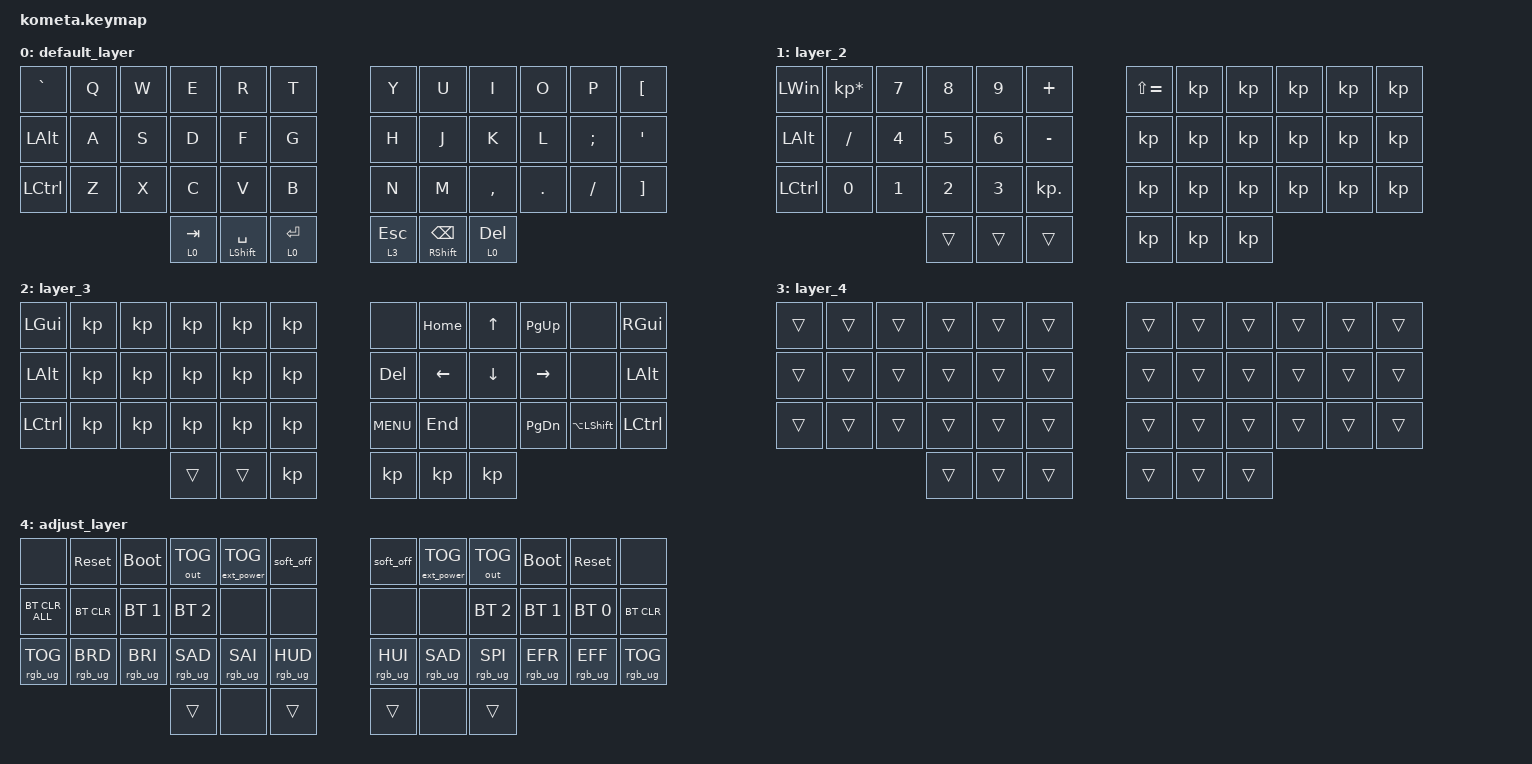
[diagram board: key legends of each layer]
#include <behaviors.dtsi>
#include <dt-bindings/zmk/bt.h>
#include <dt-bindings/zmk/ext_power.h>
#include <dt-bindings/zmk/keys.h>
#include <dt-bindings/zmk/outputs.h>
#include <dt-bindings/zmk/rgb.h>

#define DEF 0
#define LWR 1
#define RSE 2
#define ADJ 3

/ {
};

/ {
    behaviors {
        hr: hr {
            compatible = "zmk,behavior-hold-tap";
            label = "home_row";
            bindings = <&kp>, <&kp>;

            #binding-cells = <2>;
            tapping-term-ms = <150>;
            quick-tap-ms = <250>;
            flavor = "tap-preferred";
        };

        copy: copy {
            compatible = "zmk,behavior-tap-dance";
            label = "COPY";
            #binding-cells = <0>;
            bindings = <&kp C>, <&kp K_COPY>;
        };

        paste: paste {
            compatible = "zmk,behavior-tap-dance";
            label = "PASTE";
            #binding-cells = <0>;
            bindings = <&kp V>, <&kp INSERT>;
        };
    };

    keymap {
        compatible = "zmk,keymap";

        default_layer {
            bindings = <
&kp GRAVE     &kp Q  &kp W  &kp E      &kp R            &kp T      &kp Y      &kp U           &kp I      &kp O    &kp P     &kp LEFT_BRACKET
&kp LEFT_ALT  &kp A  &kp S  &kp D      &kp F            &kp G      &kp H      &kp J           &kp K      &kp L    &kp SEMI  &kp SQT
&kp LCTRL     &kp Z  &kp X  &kp C      &kp V            &kp B      &kp N      &kp M           &kp COMMA  &kp DOT  &kp FSLH  &kp RIGHT_BRACKET
                            &lt 0 TAB  &mt LSHFT SPACE  &lt 0 RET  &lt 3 ESC  &mt RSHFT BSPC  &lt 0 DEL
            >;
        };

        layer_2 {
            bindings = <
&kp LEFT_WIN  &kp KP_MULTIPLY  &kp N7        &kp N8        &kp N9        &kp PLUS    &kp LS(EQUAL)  &kp  &kp  &kp  &kp  &kp
&kp LALT      &kp SLASH        &kp NUMBER_4  &kp N5        &kp NUMBER_6  &kp MINUS   &kp            &kp  &kp  &kp  &kp  &kp
&kp LCTRL     &kp N0           &kp NUMBER_1  &kp NUMBER_2  &kp NUMBER_3  &kp KP_DOT  &kp            &kp  &kp  &kp  &kp  &kp
                                             &trans        &trans        &trans      &kp            &kp  &kp
            >;
        };

        layer_3 {
            bindings = <
&kp LEFT_GUI  &kp  &kp  &kp     &kp     &kp  &none       &kp HOME        &kp UP_ARROW    &kp PG_UP      &none               &kp RIGHT_GUI
&kp LEFT_ALT  &kp  &kp  &kp     &kp     &kp  &kp DELETE  &kp LEFT_ARROW  &kp DOWN_ARROW  &kp RIGHT      &none               &kp LEFT_ALT
&kp LCTRL     &kp  &kp  &kp     &kp     &kp  &kp C_MENU  &kp END         &none           &kp PAGE_DOWN  &kp LA(LEFT_SHIFT)  &kp LCTRL
                        &trans  &trans  &kp  &kp         &kp             &kp
            >;
        };

        layer_4 {
            bindings = <
&trans  &trans  &trans  &trans  &trans  &trans  &trans  &trans  &trans  &trans  &trans  &trans
&trans  &trans  &trans  &trans  &trans  &trans  &trans  &trans  &trans  &trans  &trans  &trans
&trans  &trans  &trans  &trans  &trans  &trans  &trans  &trans  &trans  &trans  &trans  &trans
                        &trans  &trans  &trans  &trans  &trans  &trans
            >;
        };

        adjust_layer {
            bindings = <
&none            &sys_reset       &bootloader      &out OUT_TOG     &ext_power EP_TOG  &soft_off        &soft_off        &ext_power EP_TOG  &out OUT_TOG     &bootloader      &sys_reset       &none
&bt BT_CLR_ALL   &bt BT_CLR       &bt BT_SEL 1     &bt BT_SEL 2     &none              &none            &none            &none              &bt BT_SEL 2     &bt BT_SEL 1     &bt BT_SEL 0     &bt BT_CLR
&rgb_ug RGB_TOG  &rgb_ug RGB_BRD  &rgb_ug RGB_BRI  &rgb_ug RGB_SAD  &rgb_ug RGB_SAI    &rgb_ug RGB_HUD  &rgb_ug RGB_HUI  &rgb_ug RGB_SAD    &rgb_ug RGB_SPI  &rgb_ug RGB_EFR  &rgb_ug RGB_EFF  &rgb_ug RGB_TOG
                                                   &trans           &none              &trans           &trans           &none              &trans
            >;
        };
    };
};
